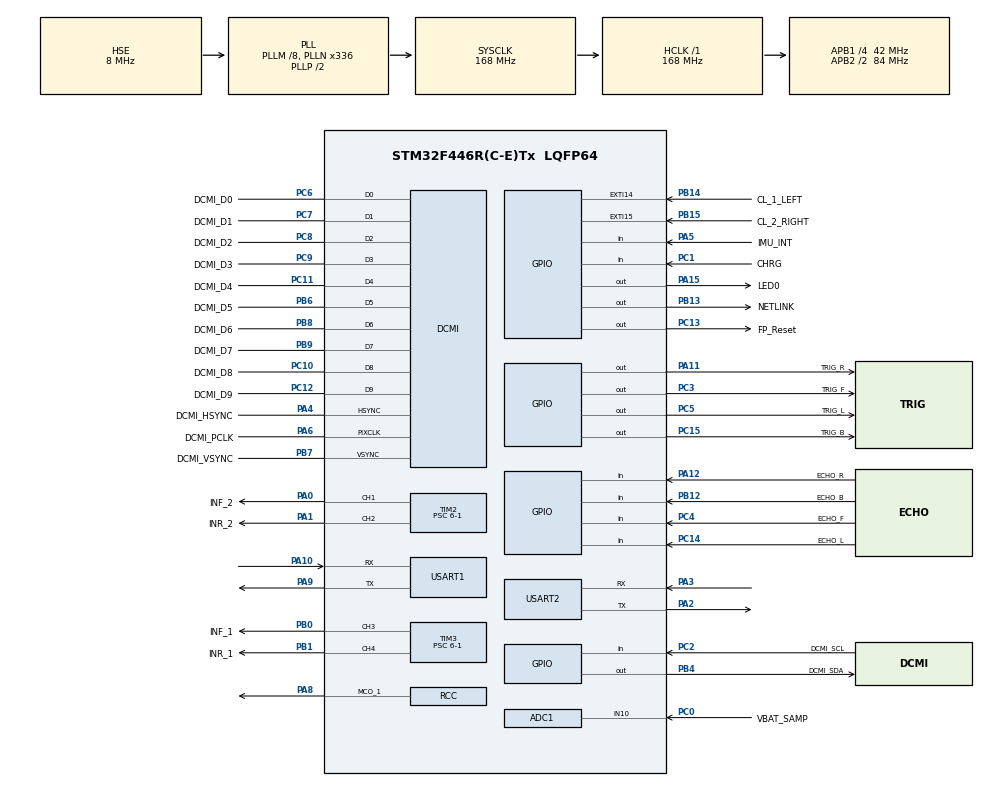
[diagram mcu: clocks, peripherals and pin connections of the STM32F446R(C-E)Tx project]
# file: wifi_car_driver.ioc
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ADC1.Channel-0\#ChannelRegularConversion=ADC_CHANNEL_10
ADC1.ContinuousConvMode=ENABLE
ADC1.NbrOfConversionFlag=1
ADC1.Rank-0\#ChannelRegularConversion=1
ADC1.SamplingTime-0\#ChannelRegularConversion=ADC_SAMPLETIME_56CYCLES
ADC1.ScanConvMode=ENABLE
ADC1.master=1
DCMI.JPEGMode=DCMI_JPEG_ENABLE
DCMI.PCKPolarity=DCMI_PCKPOLARITY_RISING
DCMI.VSPolarity=DCMI_VSPOLARITY_HIGH
Dma.ADC1.0.Direction=DMA_PERIPH_TO_MEMORY
Dma.ADC1.0.FIFOMode=DMA_FIFOMODE_DISABLE
Dma.ADC1.0.Instance=DMA2_Stream0
Dma.ADC1.0.MemDataAlignment=DMA_MDATAALIGN_HALFWORD
Dma.ADC1.0.MemInc=DMA_MINC_ENABLE
Dma.ADC1.0.Mode=DMA_CIRCULAR
Dma.ADC1.0.PeriphDataAlignment=DMA_PDATAALIGN_HALFWORD
Dma.ADC1.0.PeriphInc=DMA_PINC_DISABLE
Dma.ADC1.0.Priority=DMA_PRIORITY_HIGH
Dma.DCMI.3.Direction=DMA_PERIPH_TO_MEMORY
Dma.DCMI.3.FIFOMode=DMA_FIFOMODE_ENABLE
Dma.DCMI.3.FIFOThreshold=DMA_FIFO_THRESHOLD_FULL
Dma.DCMI.3.Instance=DMA2_Stream1
Dma.DCMI.3.MemBurst=DMA_MBURST_INC4
Dma.DCMI.3.MemDataAlignment=DMA_MDATAALIGN_WORD
Dma.DCMI.3.MemInc=DMA_MINC_ENABLE
Dma.DCMI.3.Mode=DMA_CIRCULAR
Dma.DCMI.3.PeriphBurst=DMA_PBURST_SINGLE
Dma.DCMI.3.PeriphDataAlignment=DMA_PDATAALIGN_WORD
Dma.DCMI.3.PeriphInc=DMA_PINC_DISABLE
Dma.DCMI.3.Priority=DMA_PRIORITY_HIGH
Dma.Request0=ADC1
Dma.Request1=USART1_RX
Dma.Request2=USART1_TX
Dma.Request3=DCMI
Dma.Request4=USART2_RX
Dma.Request5=USART2_TX
Dma.USART1_RX.1.Direction=DMA_PERIPH_TO_MEMORY
Dma.USART1_RX.1.FIFOMode=DMA_FIFOMODE_DISABLE
Dma.USART1_RX.1.Instance=DMA2_Stream2
Dma.USART1_RX.1.MemDataAlignment=DMA_MDATAALIGN_BYTE
Dma.USART1_RX.1.MemInc=DMA_MINC_ENABLE
Dma.USART1_RX.1.Mode=DMA_CIRCULAR
Dma.USART1_RX.1.PeriphDataAlignment=DMA_PDATAALIGN_BYTE
Dma.USART1_RX.1.PeriphInc=DMA_PINC_DISABLE
Dma.USART1_RX.1.Priority=DMA_PRIORITY_HIGH
Dma.USART1_TX.2.Direction=DMA_MEMORY_TO_PERIPH
Dma.USART1_TX.2.FIFOMode=DMA_FIFOMODE_DISABLE
Dma.USART1_TX.2.Instance=DMA2_Stream7
Dma.USART1_TX.2.MemDataAlignment=DMA_MDATAALIGN_BYTE
Dma.USART1_TX.2.MemInc=DMA_MINC_ENABLE
Dma.USART1_TX.2.Mode=DMA_NORMAL
Dma.USART1_TX.2.PeriphDataAlignment=DMA_PDATAALIGN_BYTE
Dma.USART1_TX.2.PeriphInc=DMA_PINC_DISABLE
Dma.USART1_TX.2.Priority=DMA_PRIORITY_VERY_HIGH
Dma.USART2_RX.4.Direction=DMA_PERIPH_TO_MEMORY
Dma.USART2_RX.4.FIFOMode=DMA_FIFOMODE_DISABLE
Dma.USART2_RX.4.Instance=DMA1_Stream5
Dma.USART2_RX.4.MemDataAlignment=DMA_MDATAALIGN_BYTE
Dma.USART2_RX.4.MemInc=DMA_MINC_ENABLE
Dma.USART2_RX.4.Mode=DMA_CIRCULAR
Dma.USART2_RX.4.PeriphDataAlignment=DMA_PDATAALIGN_BYTE
Dma.USART2_RX.4.PeriphInc=DMA_PINC_DISABLE
Dma.USART2_RX.4.Priority=DMA_PRIORITY_HIGH
Dma.USART2_TX.5.Direction=DMA_MEMORY_TO_PERIPH
Dma.USART2_TX.5.FIFOMode=DMA_FIFOMODE_DISABLE
Dma.USART2_TX.5.Instance=DMA1_Stream6
Dma.USART2_TX.5.MemDataAlignment=DMA_MDATAALIGN_BYTE
Dma.USART2_TX.5.MemInc=DMA_MINC_ENABLE
Dma.USART2_TX.5.Mode=DMA_NORMAL
Dma.USART2_TX.5.PeriphDataAlignment=DMA_PDATAALIGN_BYTE
Dma.USART2_TX.5.PeriphInc=DMA_PINC_DISABLE
Dma.USART2_TX.5.Priority=DMA_PRIORITY_VERY_HIGH
Mcu.Family=STM32F4
Mcu.Name=STM32F446R(C-E)Tx
Mcu.Package=LQFP64
Mcu.UserConstants=WHEEL_FREQUENCY,14000;WHEEL_PWM_PERIOD,1000;APB1_CLK_TIMER,84000000
NVIC.DCMI_IRQn=true\:0\:0\:false\:false\:true\:true
NVIC.DMA1_Stream5_IRQn=true\:0\:0\:false\:false\:true\:false
NVIC.DMA1_Stream6_IRQn=true\:0\:0\:false\:false\:true\:false
NVIC.DMA2_Stream0_IRQn=true\:0\:0\:false\:false\:true\:false
NVIC.DMA2_Stream1_IRQn=true\:0\:0\:false\:false\:true\:false
NVIC.DMA2_Stream2_IRQn=true\:0\:0\:false\:false\:true\:false
NVIC.DMA2_Stream7_IRQn=true\:0\:0\:false\:false\:true\:false
NVIC.EXTI15_10_IRQn=true\:0\:0\:false\:false\:true\:true
NVIC.PriorityGroup=NVIC_PRIORITYGROUP_4
NVIC.TIM6_DAC_IRQn=true\:0\:0\:false\:false\:true\:true
NVIC.USART1_IRQn=true\:0\:0\:false\:false\:true\:true
NVIC.USART2_IRQn=true\:0\:0\:false\:false\:true\:true
PA0-WKUP.GPIO_Label=INF_2
PA0-WKUP.Signal=S_TIM2_CH1_ETR
PA1.GPIO_Label=INR_2
PA1.Signal=S_TIM2_CH2
PA10.Mode=Asynchronous
PA10.Signal=USART1_RX
PA11.GPIO_Label=TRIG_R
PA11.Signal=GPIO_Output
PA12.GPIO_Label=ECHO_R
PA12.Signal=GPIO_Input
PA13.Mode=Serial_Wire
PA13.Signal=SYS_JTMS-SWDIO
PA14.Mode=Serial_Wire
PA14.Signal=SYS_JTCK-SWCLK
PA15.GPIO_Label=LED0
PA15.Signal=GPIO_Output
PA2.Mode=Asynchronous
PA2.Signal=USART2_TX
PA3.Mode=Asynchronous
PA3.Signal=USART2_RX
PA4.GPIO_Label=DCMI_HSYNC
PA4.Mode=Slave_10_bits_External_Synchro
PA4.Signal=DCMI_HSYNC
PA5.GPIO_Label=IMU_INT
PA5.Signal=GPIO_Input
PA6.GPIO_Label=DCMI_PCLK
PA6.Mode=Slave_10_bits_External_Synchro
PA6.Signal=DCMI_PIXCLK
PA8.Mode=Clock-out-1
PA8.Signal=RCC_MCO_1
PA9.Mode=Asynchronous
PA9.Signal=USART1_TX
PB0.GPIO_Label=INF_1
PB0.Signal=S_TIM3_CH3
PB1.GPIO_Label=INR_1
PB1.Signal=S_TIM3_CH4
PB12.GPIO_Label=ECHO_B
PB12.Signal=GPIO_Input
PB13.GPIO_Label=NETLINK
PB13.Signal=GPIO_Output
PB14.GPIO_Label=CL_1_LEFT
PB14.GPIO_ModeDefaultEXTI=GPIO_MODE_IT_RISING
PB14.Signal=GPXTI14
PB15.GPIO_Label=CL_2_RIGHT
PB15.Signal=GPXTI15
PB4.GPIO_Label=DCMI_SDA
PB4.Signal=GPIO_Output
PB6.GPIO_Label=DCMI_D5
PB6.Mode=Slave_10_bits_External_Synchro
PB6.Signal=DCMI_D5
PB7.GPIO_Label=DCMI_VSYNC
PB7.Mode=Slave_10_bits_External_Synchro
PB7.Signal=DCMI_VSYNC
PB8.GPIO_Label=DCMI_D6
PB8.Mode=Slave_10_bits_External_Synchro
PB8.Signal=DCMI_D6
PB9.GPIO_Label=DCMI_D7
PB9.Mode=Slave_10_bits_External_Synchro
PB9.Signal=DCMI_D7
PC0.GPIO_Label=VBAT_SAMP
PC0.Signal=ADCx_IN10
PC1.GPIO_Label=CHRG
PC1.Signal=GPIO_Input
PC10.GPIO_Label=DCMI_D8
PC10.Mode=Slave_10_bits_External_Synchro
PC10.Signal=DCMI_D8
PC11.GPIO_Label=DCMI_D4
PC11.Mode=Slave_10_bits_External_Synchro
PC11.Signal=DCMI_D4
PC12.GPIO_Label=DCMI_D9
PC12.Mode=Slave_10_bits_External_Synchro
PC12.Signal=DCMI_D9
PC13.GPIO_Label=FP_Reset
PC13.Signal=GPIO_Output
PC14-OSC32_IN.GPIO_Label=ECHO_L
PC14-OSC32_IN.Signal=GPIO_Input
PC15-OSC32_OUT.GPIO_Label=TRIG_B
PC15-OSC32_OUT.Signal=GPIO_Output
PC2.GPIO_Label=DCMI_SCL
PC2.Signal=GPIO_Input
PC3.GPIO_Label=TRIG_F
PC3.Signal=GPIO_Output
PC4.GPIO_Label=ECHO_F
PC4.Signal=GPIO_Input
PC5.GPIO_Label=TRIG_L
PC5.Signal=GPIO_Output
PC6.GPIO_Label=DCMI_D0
PC6.Mode=Slave_10_bits_External_Synchro
PC6.Signal=DCMI_D0
PC7.GPIO_Label=DCMI_D1
PC7.Mode=Slave_10_bits_External_Synchro
PC7.Signal=DCMI_D1
PC8.GPIO_Label=DCMI_D2
PC8.Mode=Slave_10_bits_External_Synchro
PC8.Signal=DCMI_D2
PC9.GPIO_Label=DCMI_D3
PC9.Mode=Slave_10_bits_External_Synchro
PC9.Signal=DCMI_D3
PH0-OSC_IN.Mode=HSE-External-Oscillator
PH0-OSC_IN.Signal=RCC_OSC_IN
PH1-OSC_OUT.Mode=HSE-External-Oscillator
PH1-OSC_OUT.Signal=RCC_OSC_OUT
ProjectManager.HeapSize=0x200
ProjectManager.StackSize=0x400
ProjectManager.TargetToolchain=MDK-ARM V5
RCC.AHBFreq_Value=168000000
RCC.APB1CLKDivider=RCC_HCLK_DIV4
RCC.APB1Freq_Value=42000000
RCC.APB1TimFreq_Value=84000000
RCC.APB2CLKDivider=RCC_HCLK_DIV2
RCC.APB2Freq_Value=84000000
RCC.APB2TimFreq_Value=168000000
RCC.CortexFreq_Value=168000000
RCC.HCLKFreq_Value=168000000
RCC.HSE_VALUE=8000000
RCC.PLLM=8
RCC.PLLN=336
RCC.PLLSourceVirtual=RCC_PLLSOURCE_HSE
RCC.RCC_MCO1Source=RCC_MCO1SOURCE_HSE
RCC.SYSCLKFreq_VALUE=168000000
RCC.SYSCLKSource=RCC_SYSCLKSOURCE_PLLCLK
RCC.USBFreq_Value=168000000
RCC.VCOOutputFreq_Value=336000000
SH.ADCx_IN10.0=ADC1_IN10,IN10
SH.S_TIM2_CH1_ETR.0=TIM2_CH1,PWM Generation1 CH1
SH.S_TIM2_CH2.0=TIM2_CH2,PWM Generation2 CH2
SH.S_TIM3_CH3.0=TIM3_CH3,PWM Generation3 CH3
SH.S_TIM3_CH4.0=TIM3_CH4,PWM Generation4 CH4
TIM2.Channel-PWM\ Generation1\ CH1=TIM_CHANNEL_1
TIM2.Channel-PWM\ Generation2\ CH2=TIM_CHANNEL_2
TIM2.Period=WHEEL_PWM_PERIOD
TIM2.Prescaler=6-1
TIM3.Channel-PWM\ Generation3\ CH3=TIM_CHANNEL_3
TIM3.Channel-PWM\ Generation4\ CH4=TIM_CHANNEL_4
TIM3.Period=WHEEL_PWM_PERIOD-1
TIM3.Prescaler=6-1
TIM6.Period=10
TIM6.Prescaler=84-1
USART1.VirtualMode=VM_ASYNC
USART2.VirtualMode=VM_ASYNC
VP_TIM6_VS_ClockSourceINT.Mode=Enable_Timer
board=wifi_car_driver

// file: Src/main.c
/**
  ******************************************************************************
  * @file           : main.c
  * @brief          : Main program body
  ******************************************************************************
  ** This notice applies to any and all portions of this file
  * that are not between comment pairs USER CODE BEGIN and
  * USER CODE END. Other portions of this file, whether
  * inserted by the user or by software development tools
  * are owned by their respective copyright owners.
  *
  * COPYRIGHT(c) 2018 STMicroelectronics
  *
  * Redistribution and use in source and binary forms, with or without modification,
  * are permitted provided that the following conditions are met:
  *   1. Redistributions of source code must retain the above copyright notice,
  *      this list of conditions and the following disclaimer.
  *   2. Redistributions in binary form must reproduce the above copyright notice,
  *      this list of conditions and the following disclaimer in the documentation
  *      and/or other materials provided with the distribution.
  *   3. Neither the name of STMicroelectronics nor the names of its contributors
  *      may be used to endorse or promote products derived from this software
  *      without specific prior written permission.
  *
  * THIS SOFTWARE IS PROVIDED BY THE COPYRIGHT HOLDERS AND CONTRIBUTORS "AS IS"
  * AND ANY EXPRESS OR IMPLIED WARRANTIES, INCLUDING, BUT NOT LIMITED TO, THE
  * IMPLIED WARRANTIES OF MERCHANTABILITY AND FITNESS FOR A PARTICULAR PURPOSE ARE
  * DISCLAIMED. IN NO EVENT SHALL THE COPYRIGHT HOLDER OR CONTRIBUTORS BE LIABLE
  * FOR ANY DIRECT, INDIRECT, INCIDENTAL, SPECIAL, EXEMPLARY, OR CONSEQUENTIAL
  * DAMAGES (INCLUDING, BUT NOT LIMITED TO, PROCUREMENT OF SUBSTITUTE GOODS OR
  * SERVICES; LOSS OF USE, DATA, OR PROFITS; OR BUSINESS INTERRUPTION) HOWEVER
  * CAUSED AND ON ANY THEORY OF LIABILITY, WHETHER IN CONTRACT, STRICT LIABILITY,
  * OR TORT (INCLUDING NEGLIGENCE OR OTHERWISE) ARISING IN ANY WAY OUT OF THE USE
  * OF THIS SOFTWARE, EVEN IF ADVISED OF THE POSSIBILITY OF SUCH DAMAGE.
  *
  ******************************************************************************
  */
#include "main.h"
#include "stm32f4xx_hal.h"
#include "adc.h"
#include "dcmi.h"
#include "dma.h"
#include "tim.h"
#include "usart.h"
#include "gpio.h"

/* USER CODE BEGIN Includes */
#include "app_main.h"

/* USER CODE END Includes */

/* USER CODE BEGIN PV */
/* Private variables ---------------------------------------------------------*/

/* USER CODE END PV */

void SystemClock_Config(void);

/* USER CODE BEGIN PFP */
/* Private function prototypes -----------------------------------------------*/

/* USER CODE END PFP */

int main(void)
{

  /* MCU Configuration----------------------------------------------------------*/

  /* Reset of all peripherals, Initializes the Flash interface and the Systick. */
  HAL_Init();

  /* Configure the system clock */
  SystemClock_Config();

  /* Initialize all configured peripherals */
  MX_GPIO_Init();
  MX_DMA_Init();
  MX_DCMI_Init();
  MX_USART2_UART_Init();
  MX_TIM3_Init();
  MX_TIM2_Init();
  MX_USART1_UART_Init();
  MX_ADC1_Init();
  MX_TIM6_Init();
  /* USER CODE BEGIN 2 */
	UserInit();
  /* USER CODE END 2 */

  /* Infinite loop */
  /* USER CODE BEGIN WHILE */
  while (1)
  {
		AppMainLoop();
  /* USER CODE END WHILE */

  }

}

void SystemClock_Config(void)
{

  RCC_OscInitTypeDef RCC_OscInitStruct;
  RCC_ClkInitTypeDef RCC_ClkInitStruct;

    /**Configure the main internal regulator output voltage
    */
  __HAL_RCC_PWR_CLK_ENABLE();

  __HAL_PWR_VOLTAGESCALING_CONFIG(PWR_REGULATOR_VOLTAGE_SCALE1);

    /**Initializes the CPU, AHB and APB busses clocks
    */
  RCC_OscInitStruct.OscillatorType = RCC_OSCILLATORTYPE_HSE;
  RCC_OscInitStruct.HSEState = RCC_HSE_ON;
  RCC_OscInitStruct.PLL.PLLState = RCC_PLL_ON;
  RCC_OscInitStruct.PLL.PLLSource = RCC_PLLSOURCE_HSE;
  RCC_OscInitStruct.PLL.PLLM = 8;
  RCC_OscInitStruct.PLL.PLLN = 336;
  RCC_OscInitStruct.PLL.PLLP = RCC_PLLP_DIV2;
  RCC_OscInitStruct.PLL.PLLQ = 2;
  RCC_OscInitStruct.PLL.PLLR = 2;
  if (HAL_RCC_OscConfig(&RCC_OscInitStruct) != HAL_OK)
  {
    _Error_Handler(__FILE__, __LINE__);
  }

    /**Initializes the CPU, AHB and APB busses clocks
    */
  RCC_ClkInitStruct.ClockType = RCC_CLOCKTYPE_HCLK|RCC_CLOCKTYPE_SYSCLK
                              |RCC_CLOCKTYPE_PCLK1|RCC_CLOCKTYPE_PCLK2;
  RCC_ClkInitStruct.SYSCLKSource = RCC_SYSCLKSOURCE_PLLCLK;
  RCC_ClkInitStruct.AHBCLKDivider = RCC_SYSCLK_DIV1;
  RCC_ClkInitStruct.APB1CLKDivider = RCC_HCLK_DIV4;
  RCC_ClkInitStruct.APB2CLKDivider = RCC_HCLK_DIV2;

  if (HAL_RCC_ClockConfig(&RCC_ClkInitStruct, FLASH_LATENCY_5) != HAL_OK)
  {
    _Error_Handler(__FILE__, __LINE__);
  }

  HAL_RCC_MCOConfig(RCC_MCO1, RCC_MCO1SOURCE_HSE, RCC_MCODIV_1);

    /**Configure the Systick interrupt time
    */
  HAL_SYSTICK_Config(HAL_RCC_GetHCLKFreq()/1000);

    /**Configure the Systick
    */
  HAL_SYSTICK_CLKSourceConfig(SYSTICK_CLKSOURCE_HCLK);

  /* SysTick_IRQn interrupt configuration */
  HAL_NVIC_SetPriority(SysTick_IRQn, 0, 0);
}

void _Error_Handler(char *file, int line)
{
  while(1)
  {
  }
}

/************************ (C) COPYRIGHT STMicroelectronics *****END OF FILE****/
